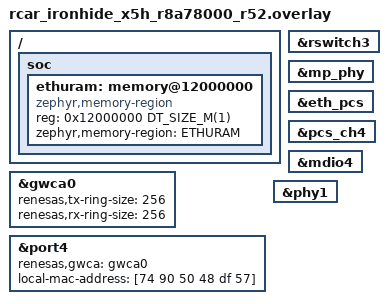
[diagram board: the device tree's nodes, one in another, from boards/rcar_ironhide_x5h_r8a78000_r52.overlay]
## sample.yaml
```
common:
  tags:
    - net
    - zperf
  platform_exclude:
    - sam_e70_xplained/same70q21
  min_ram: 64
sample:
  description: Network performance measurement tool for Zephyr
  name: zperf
tests:
  sample.net.zperf:
    harness: net
    platform_allow: qemu_x86
  sample.net.zperf_no_server:
    harness: net
    platform_allow: qemu_x86
    extra_configs:
      - CONFIG_NET_ZPERF_SERVER=n
  sample.net.zperf.async_tx.stm32:
    filter: dt_compat_enabled("st,stm32-ethernet") and CONFIG_ETH_STM32_HAL_API_V2
    harness: console
    harness_config:
      type: multi_line
      regex:
        - "coming up"
    integration_platforms:
      - stm32h573i_dk
    extra_configs:
      - CONFIG_ETH_STM32_HAL_TX_ASYNC=y
  sample.net.zperf_st:
    harness: console
    harness_config:
      type: multi_line
      regex:
        - "coming up"
    platform_allow:
      - nucleo_h563zi
      - nucleo_h743zi
      - nucleo_h753zi
      - nucleo_f429zi
      - nucleo_f746zg
      - stm32h573i_dk
    integration_platforms:
      - stm32h573i_dk
  sample.net.zperf_no_shell:
    harness: net
    extra_configs:
      - CONFIG_NET_SHELL=n
    platform_allow: qemu_x86
  sample.net.zperf_concurrent_upload:
    harness: net
    extra_configs:
      - CONFIG_ZPERF_SESSION_PER_THREAD=y
    platform_allow: qemu_x86
  sample.net.zperf.usbd_cdc_ecm:
    harness: net
    extra_args:
      - EXTRA_CONF_FILE="overlay-usbd.conf"
      - DTC_OVERLAY_FILE="usbd_cdc_ecm.overlay"
    platform_allow:
      - nrf52840dk/nrf52840
      - frdm_k64f
    tags:
      - usb
      - net
      - zperf
    depends_on: usbd
  sample.net.zperf.usbd_cdc_ncm:
    harness: net
    extra_args:
      - EXTRA_CONF_FILE="overlay-usbd.conf"
      - DTC_OVERLAY_FILE="usbd_cdc_ncm.overlay"
    platform_allow:
      - nrf52840dk/nrf52840
      - frdm_k64f
    tags:
      - usb
      - net
      - zperf
    depends_on: usbd
  sample.net.zperf.shield:
    harness: net
    platform_allow: reel_board
    extra_args: SHIELD=link_board_eth
    tags:
      - shield
      - net
      - zperf
    depends_on:
      - arduino_spi
      - arduino_gpio
  sample.net.zperf.nxp_enet1g:
    extra_args: EXTRA_DTC_OVERLAY_FILE="nxp,enet1g.overlay"
    tags:
      - net
      - zperf
    platform_allow:
      - mimxrt1170_evk/mimxrt1176/cm7
  sample.net.zperf.802154.subg:
    extra_args: EXTRA_CONF_FILE="overlay-802154-subg.conf"
    platform_allow: beagleconnect_freedom
  sample.net.zperf.nrf7002dk:
    extra_args: SNIPPET=wifi-ipv4
    extra_configs:
      - CONFIG_BUILD_ONLY_NO_BLOBS=y
    platform_allow: nrf7002dk/nrf5340/cpuapp
  sample.net.zperf.raw_tx:
    harness: net
    platform_allow: qemu_x86
    extra_configs:
      - CONFIG_NET_SOCKETS_PACKET=y
      - CONFIG_NET_ZPERF_RAW_TX=y
  sample.net.zperf.raw_tx.nrf7002dk:
    extra_args: SNIPPET=wifi-ipv4
    extra_configs:
      - CONFIG_BUILD_ONLY_NO_BLOBS=y
      - CONFIG_NET_SOCKETS_PACKET=y
      - CONFIG_NET_ZPERF_RAW_TX=y
    platform_allow: nrf7002dk/nrf5340/cpuapp
  sample.net.zperf.rcar_ironhide_x5h:
    build_only: true
    platform_allow: rcar_ironhide_x5h/r8a78000/r52
  sample.net.zperf.rcar_ironhide_x5h.port5:
    build_only: true
    platform_allow: rcar_ironhide_x5h/r8a78000/r52
    required_snippets:
      - rcar-x5h-eth-port5
  sample.net.zperf.rcar_ironhide_x5h.tsnes4:
    build_only: true
    platform_allow: rcar_ironhide_x5h/r8a78000/r52
    extra_args:
      - EXTRA_DTC_OVERLAY_FILE=boards/rcar_ironhide_x5h_r8a78000_r52_tsnes4.overlay
      - EXTRA_CONF_FILE=boards/rcar_ironhide_x5h_r8a78000_r52_tsnes4.conf
```

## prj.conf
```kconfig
CONFIG_NETWORKING=y
CONFIG_NET_ZPERF=y
CONFIG_NET_ZPERF_SERVER=y
CONFIG_NET_LOG=y
CONFIG_NET_IPV6=y
CONFIG_NET_IPV4=y
CONFIG_NET_DHCPV4=n
CONFIG_NET_UDP=y
CONFIG_NET_TCP=y
CONFIG_NET_TCP_IPV6_ND_REACHABILITY_HINT=y
CONFIG_NET_STATISTICS=y

CONFIG_NET_PKT_RX_COUNT=40
CONFIG_NET_PKT_TX_COUNT=40
CONFIG_NET_BUF_RX_COUNT=160
CONFIG_NET_BUF_TX_COUNT=160
CONFIG_NET_BUF_DATA_SIZE=1536
CONFIG_NET_IF_UNICAST_IPV6_ADDR_COUNT=4
CONFIG_NET_IF_MCAST_IPV6_ADDR_COUNT=5
CONFIG_NET_IF_UNICAST_IPV4_ADDR_COUNT=1
CONFIG_NET_MAX_CONTEXTS=5
CONFIG_NET_TC_TX_COUNT=1
CONFIG_NET_SOCKETS=y
CONFIG_NET_SOCKETS_SERVICE_THREAD_PRIO=-1
CONFIG_ZVFS_POLL_MAX=9

CONFIG_INIT_STACKS=y
CONFIG_TEST_RANDOM_GENERATOR=y

CONFIG_NET_L2_ETHERNET=y
CONFIG_NET_SHELL=y

CONFIG_NET_CONFIG_SETTINGS=y
CONFIG_NET_CONFIG_MY_IPV6_ADDR="2001:db8::1"
CONFIG_NET_CONFIG_PEER_IPV6_ADDR="2001:db8::2"
CONFIG_NET_CONFIG_MY_IPV4_ADDR="192.0.2.1"
CONFIG_NET_CONFIG_PEER_IPV4_ADDR="192.0.2.2"

CONFIG_LOG=y
CONFIG_SHELL_CMDS_RESIZE=n

CONFIG_CACHE_MANAGEMENT=y
CONFIG_SPEED_OPTIMIZATIONS=y
CONFIG_TIMESLICING=n

# For speed optimizations
CONFIG_PICOLIBC_USE_MODULE=y
```

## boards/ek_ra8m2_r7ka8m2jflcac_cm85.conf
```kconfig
CONFIG_USB_HOST_STACK=y
CONFIG_USBH_HUB_CLASS=y
CONFIG_USBH_SHELL=y

CONFIG_LOG=y
# CONFIG_UHC_DRIVER_LOG_LEVEL_WRN=n
# CONFIG_UHC_DRIVER_LOG_LEVEL_INF=n
# CONFIG_UHC_DRIVER_LOG_LEVEL_ERR=y
# CONFIG_UHC_DRIVER_LOG_LEVEL_DBG=y
CONFIG_UHC_XFER_COUNT=32
CONFIG_UHC_BUF_POOL_SIZE=8192

CONFIG_USBH_CDC_ECM_TX_PIPELINE_DEPTH=4
CONFIG_USBH_CDC_ECM_RX_PIPELINE_DEPTH=4

CONFIG_USBH_CDC_ECM_CLASS=y
# CONFIG_USBH_CDC_ECM_LOG_LEVEL_WRN=y
# CONFIG_USBH_CDC_ECM_LOG_LEVEL_ERR=y
# CONFIG_USBH_CDC_ECM_LOG_LEVEL_INF=y
CONFIG_USBH_CDC_ECM_LOG_LEVEL_DBG=y
# CONFIG_USBH_CDC_ECM_LOG_LEVEL_DEFAULT=y
# USBH
# CONFIG_USBH_LOG_LEVEL_INF=n
# CONFIG_USBH_LOG_LEVEL_ERR=y
# CONFIG_USBH_LOG_LEVEL_DBG=y

# Network - Ethernet L2
CONFIG_NET_L2_ETHERNET=y
CONFIG_NET_LOG=y
# CONFIG_NET_CORE_LOG_LEVEL_DBG=y
CONFIG_NET_TX_STACK_SIZE=2048
CONFIG_NET_RX_STACK_SIZE=2048
CONFIG_SYSTEM_WORKQUEUE_STACK_SIZE=2048
CONFIG_NET_TCP_WORKQ_STACK_SIZE=2048
CONFIG_MAIN_STACK_SIZE=4096
CONFIG_NET_TCP_WORKER_PRIO=2
CONFIG_NET_TCP_MAX_RECV_WINDOW_SIZE=65535
CONFIG_NET_TCP_MAX_SEND_WINDOW_SIZE=65535
# Network - Core
CONFIG_NETWORKING=y
CONFIG_NET_IPV4=y
CONFIG_NET_IPV6=y

CONFIG_NET_CONFIG_SETTINGS=y
CONFIG_NET_CONFIG_MY_IPV6_ADDR="2001:db8::2"
CONFIG_NET_CONFIG_PEER_IPV6_ADDR="2001:db8::1"
CONFIG_NET_CONFIG_MY_IPV4_ADDR="192.168.100.3"
CONFIG_NET_CONFIG_PEER_IPV4_ADDR="192.168.100.1"

# Shell (for basic commands)
CONFIG_SHELL=y
CONFIG_NET_SHELL=y

# Logging
CONFIG_LOG=y
CONFIG_USBH_CDC_ACM_CLASS=n
CONFIG_LOG_BUFFER_SIZE=3074
# Network Management Events
#CONFIG_NET_MGMT=y
#CONFIG_NET_MGMT_EVENT=y

CONFIG_DCACHE=y
```

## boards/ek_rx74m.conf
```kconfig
CONFIG_NET_PKT_RX_COUNT=64
CONFIG_NET_PKT_TX_COUNT=64
CONFIG_NET_BUF_RX_COUNT=160
CONFIG_NET_BUF_TX_COUNT=160
CONFIG_NET_BUF_DATA_SIZE=1536
```

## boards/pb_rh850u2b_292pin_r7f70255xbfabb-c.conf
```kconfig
# Copyright (c) 2026 Renesas Electronics Corporation
# SPDX-License-Identifier: Apache-2.0

CONFIG_NET_DHCPV4=y
CONFIG_NET_CONFIG_MY_IPV4_ADDR=""
CONFIG_NET_CONFIG_PEER_IPV4_ADDR=""
CONFIG_NET_IP_ADDR_CHECK=n
CONFIG_NET_STATISTICS=n
CONFIG_NET_IPV6=n
CONFIG_NET_PKT_RX_COUNT=40
CONFIG_NET_PKT_TX_COUNT=40
CONFIG_NET_BUF_RX_COUNT=48
CONFIG_NET_BUF_TX_COUNT=32
CONFIG_NET_BUF_DATA_SIZE=1536
CONFIG_NET_ZPERF_MAX_PACKET_SIZE=8760
CONFIG_NET_SOCKETS_SERVICE_STACK_SIZE=2048

CONFIG_SHELL_STACK_SIZE=3072

CONFIG_NET_TC_RX_COUNT=0
CONFIG_ETH_RENESAS_RH850_ETND_RX_THREAD_STACK_SIZE=2048

CONFIG_NET_TC_TX_COUNT=0
CONFIG_NET_TCP_MAX_SEND_WINDOW_SIZE=30000

# The POSIX API does not build with the IAR RH850 C library
CONFIG_POSIX_API=n
```

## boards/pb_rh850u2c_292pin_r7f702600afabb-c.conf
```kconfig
CONFIG_NET_DHCPV4=y
CONFIG_NET_IPV6=n
CONFIG_NET_CONFIG_MY_IPV4_ADDR=""
CONFIG_NET_CONFIG_PEER_IPV4_ADDR=""
CONFIG_NET_PKT_RX_COUNT=10
CONFIG_NET_PKT_TX_COUNT=10
CONFIG_NET_BUF_RX_COUNT=30
CONFIG_NET_BUF_TX_COUNT=30
CONFIG_NET_BUF_DATA_SIZE=512
CONFIG_POSIX_API=n
```

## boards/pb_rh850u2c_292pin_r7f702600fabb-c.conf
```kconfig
# Copyright (c) 2026 Renesas Electronics Corporation
# SPDX-License-Identifier: Apache-2.0

CONFIG_NET_DHCPV4=y
CONFIG_NET_IPV6=n
CONFIG_NET_CONFIG_MY_IPV4_ADDR=""
CONFIG_NET_CONFIG_PEER_IPV4_ADDR=""
CONFIG_NET_PKT_RX_COUNT=10
CONFIG_NET_PKT_TX_COUNT=10
CONFIG_NET_BUF_RX_COUNT=30
CONFIG_NET_BUF_TX_COUNT=30
CONFIG_NET_BUF_DATA_SIZE=512
CONFIG_POSIX_API=n
```

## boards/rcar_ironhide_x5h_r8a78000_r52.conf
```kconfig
# Copyright (c) 2026 Renesas Electronics Corporation
# SPDX-License-Identifier: Apache-2.0

CONFIG_NET_L2_ETHERNET=y
CONFIG_NET_STATISTICS=y
CONFIG_NET_CONFIG_MY_IPV4_ADDR=""
CONFIG_NET_CONFIG_PEER_IPV4_ADDR=""
CONFIG_NET_DHCPV4=y

# The IPv4 and IPv6 UDP/TCP servers of zperf take 4 contexts: leave room for
# the TCP connections under test.
CONFIG_NET_MAX_CONTEXTS=8

CONFIG_NET_PKT_RX_COUNT=512
CONFIG_NET_PKT_TX_COUNT=512
CONFIG_NET_BUF_RX_COUNT=512
CONFIG_NET_BUF_TX_COUNT=512
CONFIG_NET_BUF_DATA_SIZE=1536

CONFIG_NET_TX_STACK_SIZE=8192
CONFIG_NET_RX_STACK_SIZE=8192
CONFIG_NET_TCP_WORKQ_STACK_SIZE=8192
CONFIG_NET_MGMT_EVENT_STACK_SIZE=8192
CONFIG_NET_SOCKETS_SERVICE=y
CONFIG_NET_SOCKETS_SERVICE_STACK_SIZE=8192

# No traffic class threads: RX is processed on the GWCA RX thread and TX is
# pushed to the driver from the sending thread.
CONFIG_NET_TC_RX_COUNT=0
CONFIG_NET_TC_TX_COUNT=0

# Without TX traffic class threads, the whole send path runs on the zperf
# work queue.
CONFIG_ZPERF_WORK_Q_STACK_SIZE=8192
CONFIG_STACK_SENTINEL=y

# TCP window scaling (RFC 7323) for windows above 64 KB. Send window:
# rate x ACK delay of the test host (~1.5 Gbit/s x ~2 ms). Receive window:
# 2.4 Gbit/s x ~0.3 ms round trip.
CONFIG_NET_TCP_WINDOW_SCALE=y
CONFIG_NET_TCP_MAX_RECV_WINDOW_SIZE=131072
CONFIG_NET_TCP_MAX_SEND_WINDOW_SIZE=393216

# Largest UDP payload without IP fragmentation.
CONFIG_NET_ZPERF_MAX_PACKET_SIZE=1472

# GWCA RX interrupt coalescing: with the default 712.5 MHz GWCA clock this
# gives a 1 us base period and a 20 us delay.
CONFIG_ETH_RENESAS_RSWITCH3_GWCA_IRQ_DELAY_PRESCALER=712
CONFIG_ETH_RENESAS_RSWITCH3_GWCA_RX_IRQ_DELAY=20

# Network per-packet path and memcpy in the R52 ITCM
CONFIG_RCAR_GEN5_R52_ITCM_NET_HOT_PATH=y
CONFIG_RCAR_GEN5_R52_FAST_MEMCPY=y

# Tickless kernel with a 1 MHz tick: zperf paces UDP uploads per datagram
# instead of sending bursts once per tick.
CONFIG_SYS_CLOCK_TICKS_PER_SEC=1000000
```

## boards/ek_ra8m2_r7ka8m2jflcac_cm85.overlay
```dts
&usbhs {
	zephyr_uhc0: uhc {
		status = "okay";
	};
};

&eswm {
	status = "disabled";
};


&eth0 {
	status = "disabled";
};

&mdio0 {
	status = "disabled";
	phy0: phy@0 {
		status = "disabled";
	};
};
```

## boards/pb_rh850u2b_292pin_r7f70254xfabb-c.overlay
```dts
/*
 * Copyright (c) 2026 Renesas Electronics Corporation
 *
 * SPDX-License-Identifier: Apache-2.0
 */

/* PHY reset: P10_8 on board revisions 2 and 3, P12_3 on revision 1 */
&ioport10 {
	status = "okay";
};

&ioport12 {
	status = "okay";
};

&etnd0_mdio {
	status = "okay";
};

&eth_phy0 {
	status = "okay";
};

&etnd0 {
	rxb0-num = <64>;
	status = "okay";
};
```

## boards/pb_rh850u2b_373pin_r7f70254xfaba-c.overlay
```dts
/*
 * Copyright (c) 2026 Renesas Electronics Corporation
 *
 * SPDX-License-Identifier: Apache-2.0
 */

/* PHY reset on P10_8 */
&ioport10 {
	status = "okay";
};

&etnd0_mdio {
	status = "okay";
};

&eth_phy0 {
	status = "okay";
};

&etnd0 {
	rxb0-num = <64>;
	status = "okay";
};
```

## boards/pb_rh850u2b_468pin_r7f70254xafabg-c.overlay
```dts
/*
 * Copyright (c) 2026 Renesas Electronics Corporation
 *
 * SPDX-License-Identifier: Apache-2.0
 */

/* PHY reset: P10_8 on board revision 3, P12_3 on revisions 1 and 2 */
&ioport10 {
	status = "okay";
};

&ioport12 {
	status = "okay";
};

&etnd0_mdio {
	status = "okay";
};

&eth_phy0 {
	status = "okay";
};

&etnd0 {
	rxb0-num = <64>;
	status = "okay";
};
```

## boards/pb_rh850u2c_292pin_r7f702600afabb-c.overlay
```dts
/*
 * Copyright (c) 2026 Renesas Electronics Corporation
 *
 * SPDX-License-Identifier: Apache-2.0
 */

&etnf0 {
	pinctrl-0 = <&etnf0_default>;
	pinctrl-names = "default";
	local-mac-address = [74 90 50 12 34 56];
	status = "okay";

	ct25205: phy {
		status = "okay";
	};
};

&etnd0 {
	rxb0-num = <64>;
};
```

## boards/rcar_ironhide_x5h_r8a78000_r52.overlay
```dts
/*
 * Copyright (c) 2026 Renesas Electronics Corporation
 *
 * SPDX-License-Identifier: Apache-2.0
 */

&rswitch3 {
	status = "okay";
};

&gwca0 {
	status = "okay";
};

&port4 {
	status = "okay";
	renesas,gwca = <&gwca0>;
	local-mac-address = [74 90 50 48 df 57];
};

&mp_phy {
	status = "okay";
};

&eth_pcs {
	status = "okay";
};

&pcs_ch4 {
	status = "okay";
};

&mdio4 {
	status = "okay";
};

&phy1 {
	status = "okay";
};

/*
 * GWCA descriptors and frame buffers (.eth_ram) in on-chip RT-VRAM ch1
 * instead of DRAM: a cold cache line costs ~60 ns there instead of ~220 ns,
 * which the per-frame copies and descriptor accesses hit on every frame.
 */
/delete-node/ &ethuram;

/ {
	soc {
		ethuram: memory@12000000 {
			compatible = "zephyr,memory-region";
			reg = <0x12000000 DT_SIZE_M(1)>;
			zephyr,memory-region = "ETHURAM";
			status = "okay";
		};
	};
};

/* The GWCA DMA area is 1 MB of RT-VRAM: 256 RX + 256 TX slots of 1536 bytes. */
&gwca0 {
	renesas,tx-ring-size = <256>;
	renesas,rx-ring-size = <256>;
};
```

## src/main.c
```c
/*
 * Copyright (c) 2020 Nordic Semiconductor ASA
 *
 * SPDX-License-Identifier: Apache-2.0
 */

/**
 * @file
 * @brief Zperf sample.
 */
#include <string.h>

#include <zephyr/kernel.h>
#include <zephyr/usb/usbd.h>
#include <zephyr/net/net_config.h>

LOG_MODULE_REGISTER(zperf, CONFIG_NET_ZPERF_LOG_LEVEL);

#ifdef CONFIG_NET_LOOPBACK_SIMULATE_PACKET_DROP
#include <zephyr/net/loopback.h>
#endif

#if defined(CONFIG_USB_DEVICE_STACK_NEXT)
#include <sample_usbd.h>
#endif

#if defined(CONFIG_ZPERF_LOOPBACK_SELFTEST)
#include <zephyr/net/net_ip.h>
#include <zephyr/net/zperf.h>

#define SELFTEST_PORT        CONFIG_ZPERF_LOOPBACK_SELFTEST_PORT
#define SELFTEST_DURATION_MS CONFIG_ZPERF_LOOPBACK_SELFTEST_DURATION_MS
#define SELFTEST_PACKET_SIZE CONFIG_ZPERF_LOOPBACK_SELFTEST_PACKET_SIZE
#define SELFTEST_RATE_KBPS   CONFIG_ZPERF_LOOPBACK_SELFTEST_RATE_KBPS
#define SELFTEST_FRAG_PACKET_SIZE CONFIG_ZPERF_LOOPBACK_SELFTEST_FRAG_PACKET_SIZE

/* Non-default socket priority applied to every upload so that, when more than
 * one traffic class is configured, traffic is routed through the per-traffic-
 * class threads (net_tc.c) instead of the caller's context. Set to -1 (i.e. do
 * not set SO_PRIORITY) when priority support is not compiled in.
 */
#if defined(CONFIG_NET_CONTEXT_PRIORITY)
#define SELFTEST_PRIORITY NET_PRIORITY_VI
#else
#define SELFTEST_PRIORITY (-1)
#endif

/* Loopback addresses used for both the server bind and the client connect.
 * The loopback driver assigns 127.0.0.1 and ::1 to the loopback interface, so
 * both are valid local endpoints.
 */
#define SELFTEST_IPV4_ADDR   "127.0.0.1"
#define SELFTEST_IPV6_ADDR   "::1"

/* When the configured rate is 0 (unlimited), the runner picks a rate high
 * enough that the per-packet pacing delay in the UDP uploader rounds down to
 * zero, so the client sends as fast as the (virtual) CPU allows. The computed
 * rate (in kbps) is stored in a uint32_t field, so it must fit; the math below
 * is done in 64-bit to avoid an intermediate overflow. This bounds the usable
 * packet size at roughly 500 kB, far above any realistic MTU.
 */
BUILD_ASSERT(((uint64_t)SELFTEST_PACKET_SIZE * 8U * 1000000U) / 1024U + 1U <=
		     UINT32_MAX,
	     "Unlimited-rate loopback selftest packet size overflows rate_kbps");
BUILD_ASSERT(((uint64_t)SELFTEST_FRAG_PACKET_SIZE * 8U * 1000000U) / 1024U + 1U <=
		     UINT32_MAX,
	     "Unlimited-rate loopback selftest frag packet size overflows rate_kbps");

static void selftest_session_cb(enum zperf_status status,
				struct zperf_results *result,
				void *user_data)
{
	ARG_UNUSED(status);
	ARG_UNUSED(result);
	ARG_UNUSED(user_data);
}

/* Fill a socket address with the loopback endpoint for the given family. */
static void selftest_fill_addr(struct net_sockaddr *addr, int family)
{
	if (family == NET_AF_INET6) {
		struct net_sockaddr_in6 *a6 = net_sin6(addr);

		memset(a6, 0, sizeof(*a6));
		a6->sin6_family = NET_AF_INET6;
		a6->sin6_port = net_htons(SELFTEST_PORT);
		(void)net_addr_pton(NET_AF_INET6, SELFTEST_IPV6_ADDR,
				    &a6->sin6_addr);
	} else {
		struct net_sockaddr_in *a4 = net_sin(addr);

		memset(a4, 0, sizeof(*a4));
		a4->sin_family = NET_AF_INET;
		a4->sin_port = net_htons(SELFTEST_PORT);
		(void)net_addr_pton(NET_AF_INET, SELFTEST_IPV4_ADDR,
				    &a4->sin_addr);
	}
}

static void selftest_fill_upload(struct zperf_upload_params *param, int family,
				 uint32_t packet_size, bool tcp_nodelay)
{
	uint32_t rate_kbps = SELFTEST_RATE_KBPS;

	if (rate_kbps == 0U) {
		/* Force packet_duration_us == 0, i.e. no pacing. Compute in
		 * 64-bit to avoid overflowing the intermediate product for
		 * near-MTU packet sizes, then store the (small enough) result.
		 */
		rate_kbps = (uint32_t)(((uint64_t)packet_size * 8U *
					1000000U) / 1024U + 1U);
	}

	memset(param, 0, sizeof(*param));
	selftest_fill_addr(net_sad(&param->peer_addr_storage), family);
	param->duration_ms = SELFTEST_DURATION_MS;
	param->packet_size = packet_size;
	param->rate_kbps = rate_kbps;
	param->unix_offset_us = (uint64_t)k_uptime_get() * USEC_PER_MSEC;
	param->options.priority = SELFTEST_PRIORITY;
	param->options.tcp_nodelay = tcp_nodelay ? 1 : 0;
}

/* Machine-parseable throughput line for the twister console harness. */
static void selftest_report(const char *proto, struct zperf_results *res)
{
	uint64_t kbps = 0U;

	if (res->client_time_in_us != 0U) {
		kbps = ((uint64_t)res->nb_packets_sent *
			(uint64_t)res->packet_size * 8U * USEC_PER_SEC) /
		       ((uint64_t)res->client_time_in_us * 1000U);
	}

	printk("ZPERF-RESULT %s_mbps=%u.%03u\n", proto,
	       (uint32_t)(kbps / 1000U), (uint32_t)(kbps % 1000U));
}

static int selftest_run_udp(int family, const char *label, uint32_t packet_size)
{
	struct zperf_download_params dl = { .port = SELFTEST_PORT };
	struct zperf_upload_params ul;
	struct zperf_results res = { 0 };
	int ret;

	/* Bind the receiver to the loopback address so the client can reach it
	 * (in particular ::1, which is not the interface's default address).
	 */
	selftest_fill_addr(&dl.addr, family);

	ret = zperf_udp_download(&dl, selftest_session_cb, NULL);
	if (ret < 0) {
		return ret;
	}

	selftest_fill_upload(&ul, family, packet_size, false);
	ret = zperf_udp_upload(&ul, &res);
	(void)zperf_udp_download_stop();
	if (ret < 0) {
		return ret;
	}

	selftest_report(label, &res);

	return 0;
}

static int selftest_run_tcp(int family, const char *label, bool tcp_nodelay)
{
	struct zperf_download_params dl = { .port = SELFTEST_PORT };
	struct zperf_upload_params ul;
	struct zperf_results res = { 0 };
	int ret;

	selftest_fill_addr(&dl.addr, family);

	ret = zperf_tcp_download(&dl, selftest_session_cb, NULL);
	if (ret < 0) {
		return ret;
	}

	selftest_fill_upload(&ul, family, SELFTEST_PACKET_SIZE, tcp_nodelay);
	ret = zperf_tcp_upload(&ul, &res);
	(void)zperf_tcp_download_stop();
	if (ret < 0) {
		return ret;
	}

	selftest_report(label, &res);

	return 0;
}

/* Whether the extra, intentionally-fragmenting UDP run should be performed for
 * the given family (needs the matching IP fragmentation support compiled in).
 */
static bool selftest_frag_enabled(int family)
{
	if (family == NET_AF_INET6) {
		return IS_ENABLED(CONFIG_NET_IPV6_FRAGMENT);
	}

	return IS_ENABLED(CONFIG_NET_IPV4_FRAGMENT);
}

static void selftest_run_family(int family, const char *udp_label,
				const char *udp_frag_label,
				const char *tcp_label,
				const char *tcp_nodelay_label)
{
	int ret;

	ret = selftest_run_udp(family, udp_label, SELFTEST_PACKET_SIZE);
	if (ret < 0) {
		printk("ZPERF-RESULT %s_mbps=error(%d)\n", udp_label, ret);
	}

	/* Oversized datagram: forces IP fragmentation on TX and reassembly on
	 * RX. Only meaningful when fragmentation is compiled in.
	 */
	if (selftest_frag_enabled(family)) {
		ret = selftest_run_udp(family, udp_frag_label,
				       SELFTEST_FRAG_PACKET_SIZE);
		if (ret < 0) {
			printk("ZPERF-RESULT %s_mbps=error(%d)\n",
			       udp_frag_label, ret);
		}
	}

	ret = selftest_run_tcp(family, tcp_label, false);
	if (ret < 0) {
		printk("ZPERF-RESULT %s_mbps=error(%d)\n", tcp_label, ret);
	}

	/* Same transfer with Nagle disabled to cover the TCP_NODELAY send path. */
	ret = selftest_run_tcp(family, tcp_nodelay_label, true);
	if (ret < 0) {
		printk("ZPERF-RESULT %s_mbps=error(%d)\n", tcp_nodelay_label,
		       ret);
	}
}

static void run_loopback_selftest(void)
{
	if (IS_ENABLED(CONFIG_NET_IPV4)) {
		selftest_run_family(NET_AF_INET, "udp4", "udp4_frag", "tcp4",
				    "tcp4_nodelay");
	}

	if (IS_ENABLED(CONFIG_NET_IPV6)) {
		selftest_run_family(NET_AF_INET6, "udp6", "udp6_frag", "tcp6",
				    "tcp6_nodelay");
	}

	printk("ZPERF-DONE\n");
}
#endif /* CONFIG_ZPERF_LOOPBACK_SELFTEST */
#if defined(CONFIG_USB_HOST_STACK)
#include <zephyr/usb/usbh.h>
#include <zephyr/drivers/usb/uhc.h>
#include <zephyr/net/net_mgmt.h>
#include <zephyr/net/net_event.h>

USBH_CONTROLLER_DEFINE(sample_uhs_ctx, DEVICE_DT_GET(DT_NODELABEL(zephyr_uhc0)));

#if defined(CONFIG_NET_CONFIG_SETTINGS)
static struct net_mgmt_event_callback usbh_iface_cb;

static void usbh_iface_up_handler(struct net_mgmt_event_callback *cb,
				  uint64_t mgmt_event, struct net_if *iface)
{
	if (mgmt_event != NET_EVENT_IF_UP) {
		return;
	}

	LOG_INF("USB host interface up, configuring static IP");
	(void)net_config_init_app(NULL, "USB host network");
}
#endif /* CONFIG_NET_CONFIG_SETTINGS */

static int zperf_usbh_init(void)
{
	int ret;

#if defined(CONFIG_NET_CONFIG_SETTINGS)
	net_mgmt_init_event_callback(&usbh_iface_cb, usbh_iface_up_handler,
				     NET_EVENT_IF_UP);
	net_mgmt_add_event_callback(&usbh_iface_cb);
#endif

	ret = usbh_init(&sample_uhs_ctx);
	if (ret) {
		LOG_ERR("Failed to init USB host: %d", ret);
		return ret;
	}

	ret = usbh_enable(&sample_uhs_ctx);
	if (ret) {
		LOG_ERR("Failed to enable USB host: %d", ret);
		return ret;
	}

	ret = uhc_bus_reset(sample_uhs_ctx.dev);
	if (ret) {
		LOG_ERR("Failed to signal bus reset: %d", ret);
		return ret;
	}

	ret = uhc_bus_resume(sample_uhs_ctx.dev);
	if (ret) {
		LOG_ERR("Failed to signal bus resume: %d", ret);
		return ret;
	}

	ret = uhc_sof_enable(sample_uhs_ctx.dev);
	if (ret) {
		LOG_ERR("Failed to enable SoF: %d", ret);
		return ret;
	}

	return 0;
}
SYS_INIT(zperf_usbh_init, APPLICATION, 94);
#endif /* CONFIG_USB_HOST_STACK */);

int main(void)
{
#if defined(CONFIG_USB_DEVICE_STACK_NEXT)
	struct usbd_context *sample_usbd;
	int err;

	sample_usbd = sample_usbd_init_device(NULL);
	if (sample_usbd == NULL) {
		return -ENODEV;
	}

	err = usbd_enable(sample_usbd);
	if (err) {
		return err;
	}

	(void)net_config_init_app(NULL, "Initializing network");
#endif /* CONFIG_USB_DEVICE_STACK_NEXT */

#ifdef CONFIG_NET_LOOPBACK_SIMULATE_PACKET_DROP
	loopback_set_packet_drop_ratio(1);
#endif

#if defined(CONFIG_NET_DHCPV4) && !defined(CONFIG_NET_CONFIG_SETTINGS)
	net_dhcpv4_start(net_if_get_default());
#endif

#if defined(CONFIG_ZPERF_LOOPBACK_SELFTEST)
	run_loopback_selftest();
#endif /* CONFIG_ZPERF_LOOPBACK_SELFTEST */

	return 0;
}
```
